AUTOSAR XML (schema 4-1-3)
standard types defined: boolean, uint8
package /UAES/ASW/CompuMethods
  compu method CM_boolean: 0=FALSE, 1=TRUE
package /UAES/ASW/DataConstrs
  range DC_boolean: raw 0..1
  range DC_uint8: raw 0..255
package /UAES/ASW/DataTypeMappingSets
  data type mapping set EFuse_ComCnvRx
package /UAES/ASW/PortInterfaces
  5 x sender receiver interface:
    ComRx_u8UMM_UsageModeSt: invalidation-policy{data-element=ComRx_u8UMM_UsageModeSt/Val, handle-invalid=DONT-INVALIDATE}
      data Val: sw-calibration-access=READ-ONLY, type=uint8
    EFuse_flgPreSleep: invalidation-policy{data-element=EFuse_flgPreSleep/Val, handle-invalid=DONT-INVALIDATE}
      data Val: sw-calibration-access=READ-ONLY, type=boolean
    EFuse_flgPwrModChng: invalidation-policy{data-element=EFuse_flgPwrModChng/Val, handle-invalid=DONT-INVALIDATE}
      data Val: sw-calibration-access=READ-ONLY, type=boolean
    gAppEcuM_u8EfuseGetLocHoldFlag: invalidation-policy{data-element=gAppEcuM_u8EfuseGetLocHoldFlag/Val, handle-invalid=DONT-INVALIDATE}
      data Val: sw-calibration-access=READ-ONLY, type=uint8
    ModeM_u8EfuseGetLocHoldFlag: invalidation-policy{data-element=ModeM_u8EfuseGetLocHoldFlag/Val, handle-invalid=DONT-INVALIDATE}
      data Val: sw-calibration-access=READ-ONLY, type=uint8
package /UAES/ASW/SwComponentTypes
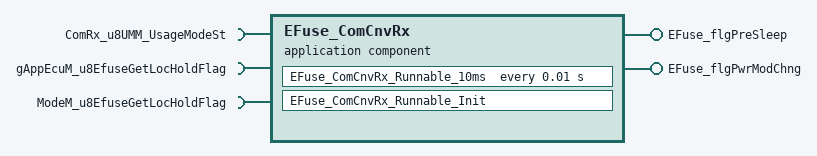
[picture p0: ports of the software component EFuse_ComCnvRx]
  application sw component type EFuse_ComCnvRx
    provide port EFuse_flgPreSleep: nonqueued-sender-com-spec{data-element=EFuse_flgPreSleep/Val, init-value=0}, provided-interface=EFuse_flgPreSleep
    provide port EFuse_flgPwrModChng: nonqueued-sender-com-spec{data-element=EFuse_flgPwrModChng/Val, init-value=0}, provided-interface=EFuse_flgPwrModChng
    require port ComRx_u8UMM_UsageModeSt: nonqueued-receiver-com-spec{data-element=ComRx_u8UMM_UsageModeSt/Val, filter=data-filter-type=ALWAYS, init-value=0}, required-interface=ComRx_u8UMM_UsageModeSt
    require port gAppEcuM_u8EfuseGetLocHoldFlag: nonqueued-receiver-com-spec{data-element=gAppEcuM_u8EfuseGetLocHoldFlag/Val, filter=data-filter-type=ALWAYS, init-value=0}, required-interface=gAppEcuM_u8EfuseGetLocHoldFlag
    require port ModeM_u8EfuseGetLocHoldFlag: nonqueued-receiver-com-spec{data-element=ModeM_u8EfuseGetLocHoldFlag/Val, filter=data-filter-type=ALWAYS, init-value=0}, required-interface=ModeM_u8EfuseGetLocHoldFlag
    behavior EFuse_ComCnvRx_InternalBehavior: data-type-mapping=EFuse_ComCnvRx
      timing event TMT_EFuse_ComCnvRx_Runnable_10ms: start-on-event=EFuse_ComCnvRx_Runnable_10ms, period=0.01
      init event EFuse_ComCnvRx_Runnable_InitEvent: start-on-event=EFuse_ComCnvRx_Runnable_Init
      runnable EFuse_ComCnvRx_Runnable_10ms
        data-read-access:
          access READ_ComRx_u8UMM_UsageModeSt_Val: accessed-variable=ComRx_u8UMM_UsageModeSt.Val
          access READ_gAppEcuM_u8EfuseGetLocHoldFlag_Val: accessed-variable=gAppEcuM_u8EfuseGetLocHoldFlag.Val
          access READ_ModeM_u8EfuseGetLocHoldFlag_Val: accessed-variable=ModeM_u8EfuseGetLocHoldFlag.Val
        data-write-access:
          access WRITE_EFuse_flgPreSleep_Val: accessed-variable=EFuse_flgPreSleep.Val
          access WRITE_EFuse_flgPwrModChng_Val: accessed-variable=EFuse_flgPwrModChng.Val
      runnable EFuse_ComCnvRx_Runnable_Init
  swc implementation EFuse_ComCnvRx_Implementation: behavior=EFuse_ComCnvRx_InternalBehavior
    code-descriptors:
      code Default: artifact-descriptors=autosar-engineering-object={short-label=Default, category=SWSRC}
package /UAES/ASW/Units
  unit NoUnit: factor-si-to-unit=1, offset-si-to-unit=0
